# SF32LB56x register map
File version: 1.0
CPU: CM33 r0p1, little endian, MPU, FPU, 3 interrupt priority bits
Registers are 32-bit, read-write, reset 0x0 unless marked. A register's access mark holds for its fields unless they carry their own. Offsets are from the block's base; [hi:lo] are bit positions.

## MPI1
Base 0x40081000
Same registers: MPI2 0x40082000, MPI3 0x40083000, MPI4 0x40084000, MPI5 0x50081000
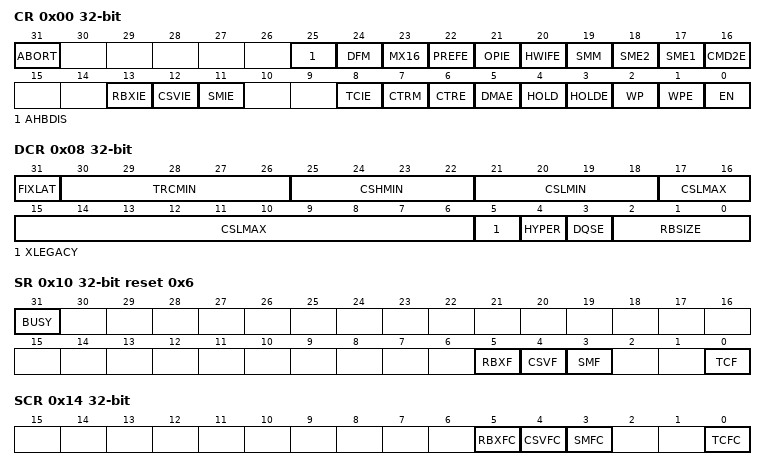
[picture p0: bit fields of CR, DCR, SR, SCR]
0x00 CR — Control Register
  [31] ABORT — Write 1 to abort internal state machine. For debug purpose only
  [25] AHBDIS — Hold hreadyout low if AHB access
  [24] DFM — Dual Flash ModeReserved-Do not modify
  [23] MX16 — Mode X16Reserved-Do not modify
  [22] PREFE — Prefetch enable. If enabled, MPI will prefetch at consequtive address following a read transaction. Recommend to use when reading large data in a burst manner. 0: prefetch disabled 1: prefetch enabled
  [21] OPIE — OPI interface enable 0: x8 mode disabled 1: x8 mode enabled
  [20] HWIFE — Hardware interface enableReserved-Do not modify
  [19] SMM — Status match mode 0: AND mode 1: OR mode
  [18] SME2 — Status match enable. If enabled, CMD2 will be issued repeatedly until the data match the value in SMR and SMKR 0: disabled 1: enabled
  [17] SME1 — Status match enable. If enabled, CMD1 will be issued repeatedly until the data match the value in SMR and SMKR 0: disabled 1: enabled (either SME1 or SME2 can be enabled, and SME1 has high priority)
  [16] CMD2E — Enable CMD2 0: disabled 1: CMD2 is enabled and will be issued after CMD1 with an interval of TI2
  [13] RBXIE — Row boundary crossing interrupt enable
  [12] CSVIE — CS max violation interrupt enable
  [11] SMIE — Status match interrupt enable
  [8] TCIE — Transfer complete interrupt enable
  [7] CTRM — AES-CTR mode 0: AES-128 1: AES-256
  [6] CTRE — AES-CTR on-the-fly decryption enable 0: disabled 1: enabled, data read from memory will be decrypted on the fly by MPI controller
  [5] DMAE — DMA enable 0: disabled 1: enable DMA to read or write DR register
  [4] HOLD — The value of HOLD when HOLDE is set
  [3] HOLDE — Enable HOLD function on IO3. Use this only in SPI or Dual SPI mode
  [2] WP — The value of WP when WPE is set
  [1] WPE — Enable WP function on IO2. Use this only in SPI or Dual SPI mode
  [0] EN — Enable MPI
0x04 DR — Data Register
  [31:0] DATA — The entry of internal data FIFO
0x08 DCR — Device Control Register
  [31] FIXLAT — Indicate PSRAM is fixed latency or variable latency. It must be compatible to the configuration in PSRAM registers. Recommend always set to 1. 0: variable latency 1: fixed latency
  [30:26] TRCMIN — Write/Read cycle minimum time in internal MCLK cycles. Please see MCLK frequency in PSCLR description. For example, if PSRAM clock is 120MHz (i.e. internal MCLK is 240MHz) and TRCMIN = n, then tRC time = (n+1) * 1000/240 ns which must meet minimum tRC requirement for PSRAM
  [25:22] CSHMIN — Minimum CS high deselect time in MCLK cycles. For example, if PSRAM clock is 120MHz (i.e. internal MCLK is 240MHz) and CSHMIN = n, then CS High time = (n+1) * 1000/240 ns which must meet minimum tCPH requirement for PSRAM
  [21:18] CSLMIN — Minimum CS low active time in MCLK cycles. For example, if PSRAM clock is 120MHz (i.e. internal MCLK is 240MHz) and CSLMIN = n, then CS Low time = (n+1) * 1000/240 ns which must meet the minimum tCEM requirement for PSRAM
  [17:6] CSLMAX — Maximum CS low active time in MCLK cycles For example, if PSRAM clock is 120MHz (i.e. internal MCLK is 240MHz) and CSLMAX = n, then CS Low time = (n+1) * 1000/240 ns which must meet the maximum tCEM requirement for PSRAM
  [5] XLEGACY — Xccela legacy protocol. Set to 1 for AP 32Mb PSRAM only, othersize always set to 0.
  [4] HYPER — HyperBus protocol. Set to 1 for HyperRAM.
  [3] DQSE — DQS enable. Setting to 1 indicates device provides DQS signal for Rx data latching
  [2:0] RBSIZE — Row boundary size. 0: no row boundary 1: 2^(1+3) = 16 bytes 2: 2^(2+3) = 32 bytes … n: 2^(n+3) bytes
0x0C PSCLR — Prescaler Register
  [7:0] DIV — Prescaler divider. 0: MCLK = FCLK/1 1: MCLK = FCLK/1 2: MCLK = FCLK/2 n: MCLK = FCLK/n Note: FLASH clock = MCLK. E.g. FCLK=192M and DIV=2, then FLASH clock = MCLK = 192/2 = 96MHz PSRAM clock = MCLK/2. E.g. FCLK=240M and DIV=1, then PSRAM clock = MCLK/2 = 240/2 = 120MHz
0x10 SR reset 0x6 — Status Register
  [31] BUSY — For debug purpose only
  [5] RBXF — Row boundary crossing flag
  [4] CSVF — CS max violation flag
  [3] SMF — Status match flag in Polling Mode
  [0] TCF — Transfer complete flag
0x14 SCR — Status Clear Register
  [5] RBXFC — Write 1 to clear RBXF
  [4] CSVFC — Write 1 to clear CSVF
  [3] SMFC — Write 1 to clear SMF
  [0] TCFC — Write 1 to clear TCF
0x18 CMDR1 — Command Register
  [7:0] CMD — Command. Write to this register will trigger the sequence specified in CCR1
0x1C AR1 — Address Register
  [31:0] ADDR — Address
0x20 ABR1 — Alternate Byte Register
  [31:0] ABYTE — Alternate byte
0x24 DLR1 — Data Length Register
  [19:0] DLEN — Data length 0: one byte 1: two bytes … n: (n+1) bytes
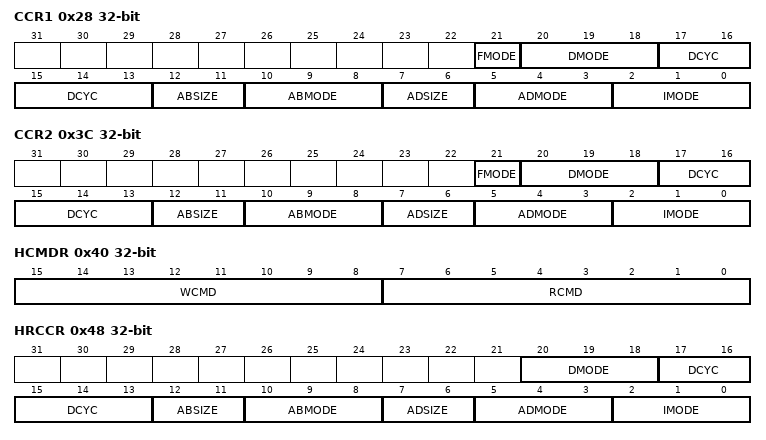
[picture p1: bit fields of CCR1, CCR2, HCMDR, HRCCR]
0x28 CCR1 — Communication Configuration Register
  [21] FMODE — Function Mode 0: read mode 1: write mode
  [20:18] DMODE — Data Mode 0: no data phase 1: single line 2: dual lines 3: quad lines 4/5/6: reserved 7: quad lines DDR
  [17:13] DCYC — Number of dummy cycles 0: no dummy cycle 1: one dummy cycle 2: two dummy cycles
  [12:11] ABSIZE — Alternate byte size 0: one byte 1: two bytes 2: three bytes 3: four bytes
  [10:8] ABMODE — Alternate byte mode 0: no alternate byte 1: single line 2: dual lines 3: quad lines 4/5/6: reserved 7: quad lines DDR
  [7:6] ADSIZE — Address size 0: one byte 1: two bytes 2: three bytes 3: four bytes
  [5:3] ADMODE — Address mode 0: no address phase 1: single line 2: dual line 3: quad line 4/5/6: reserved 7: quad line DDR
  [2:0] IMODE — Instruction mode 0: no instruction phase 1: single line 2: dual lines 3: quad lines 4/5/6 - reserved 7 - quad lines DDR
0x2C CMDR2 — Command Register
  [7:0] CMD — Command 2. If CMD2E is enabled, the CMD2 sequence will be issued after CMD1 as specified in CCR2 Note: CMD2 sequence cannot be issue individually
0x30 AR2 — Address Register
  [31:0] ADDR — Address byte in CMD2 sequence
0x34 ABR2 — Alternate Byte Register
  [31:0] ABYTE — Alternate byte in CMD2 sequence
0x38 DLR2 — Data Length Register
  [19:0] DLEN — Data length in CMD2 sequence
0x3C CCR2 — Communication Configuration Register
  [21] FMODE
  [20:18] DMODE
  [17:13] DCYC
  [12:11] ABSIZE
  [10:8] ABMODE
  [7:6] ADSIZE
  [5:3] ADMODE
  [2:0] IMODE — This register specifies the format of CMD2 sequence. Refer to CCR1 description
0x40 HCMDR — AHB Command Register
  [15:8] WCMD — AHB write command. During XIP, the AHB write transaction will be translated into this Write Command on memory interface
  [7:0] RCMD — AHB read command. During XIP, the AHB read transaction will be translated into this Read Command on memory interface
0x44 HRABR — AHB Read Alternate Byte Register
  [31:0] ABYTE
0x48 HRCCR — AHB Read Communication Configuration Register
  [20:18] DMODE
  [17:13] DCYC
  [12:11] ABSIZE
  [10:8] ABMODE
  [7:6] ADSIZE
  [5:3] ADMODE
  [2:0] IMODE — This register specifies the format of AHB read command sequence. Refer to CCR1 description
0x4C HWABR — AHB Write Alternate Byte Register
  [31:0] ABYTE
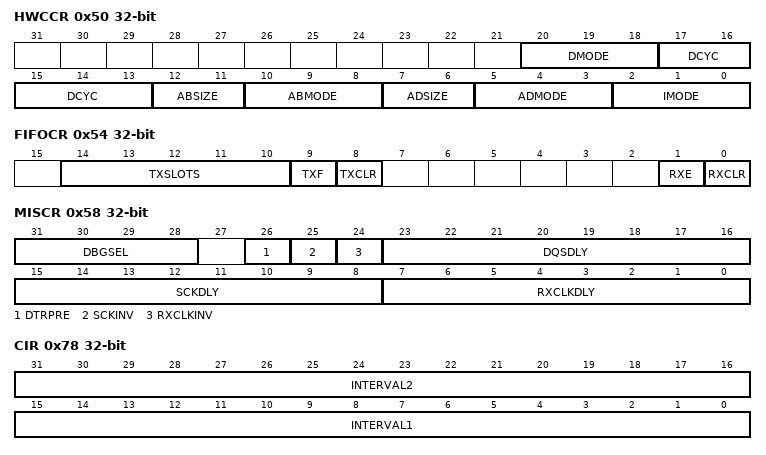
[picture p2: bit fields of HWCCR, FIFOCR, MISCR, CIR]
0x50 HWCCR — AHB Write Communication Configuration Register
  [20:18] DMODE
  [17:13] DCYC
  [12:11] ABSIZE
  [10:8] ABMODE
  [7:6] ADSIZE
  [5:3] ADMODE
  [2:0] IMODE — This register specifies the format of AHB write command sequence. Refer to CCR1 description
0x54 FIFOCR — FIFO Control Register
  [14:10] TXSLOTS — When DMA enabled, asserts DMA reqeust if TXFIFO vacant slots is greater than or equal to TXSLOTS. Note: this field should be set in accordance to the burst length in DMA. For example, if DMA employs BURST8 transction, then this filed is set to 8
  [9] TXF — Tx FIFO full flag
  [8] TXCLR — write 1 to clear Tx FIFO
  [1] RXE — Rx FIFO empty
  [0] RXCLR — write 1 to clear Rx FIFO
0x58 MISCR — Miscelaneous Register
  [31:28] DBGSEL
  [26] DTRPRE — Enable pre-sampling for DTRReserved-Do not modify
  [25] SCKINV — Invert output clock. This bit is used to align (coarse tune) the output clock to the center of output data.
  [24] RXCLKINV — Invert internal Rx clock to add half-cycle delay (coarse tune) when sampling data. It is usually used for FLASH device w/ higher frequency.
  [23:16] DQSDLY — Delay the input DQS signal to the appropriate sampling position. For device w/ DQS signal only. Note: effective 7-bit
  [15:8] SCKDLY — Add delay on output clock to fine tune the clock position. Note: effective 7-bit
  [7:0] RXCLKDLY — Add delay on internal Rx clock to fine tune the sampling position. Note: effective 5-bit
0x5C CTRSAR — CTR Starting Address Register
  [31:10] SA — Starting address of the AES decryption area. Since the lowest 10 bits are zero, the address is always 1KB aligned. Together with CTREAR, the total area is [CTRSAR, CTREAR) For example, CTRSAR = 32'h0, CTREAR = 32'h200000, then the on-the-fly decryption area is 0x0 - 0x1FFFFF
0x60 CTREAR — CTR Ending Address Register
  [31:10] EA — Ending address of the AES decryption area
0x64 NONCEA
  [31:0] NONCEA — Used for on-the-fly decryption
0x68 NONCEB
  [31:0] NONCEB — Used for on-the-fly decryption
0x6C AASAR — Address Aliasing Start Address Register
  [31:10] SA — Starting address of the address aliasing area. Always 1KB aligned.Together with AAEAR, the aliasing area is [AASAR, AAEAR). If the address falls into this area, an offset AAOAR is added and the aliased address will be used to access external memory
0x70 AAEAR — Address Aliasing Ending Address Register
  [31:10] EA — Ending address of the address aliasing area
0x74 AAOAR — Address Aliasing Offset Address Register
  [31:10] OA — The offset to be added to the original address
0x78 CIR — Command Interval Register
  [31:16] INTERVAL2 — The interval between CMD1 and CMD2 (or between CMD2 itself) if CMD2E is enabled. The unit is in MCLK cycles
  [15:0] INTERVAL1 — The interval between CMD1 itself. The unit is in MCLK cycles
0x7C SMR — Status Match Register
  [31:0] STATUS — If status match is enabled, this register is compared with the data read from external memory. Together with SMKR, only the bits with mask=1 will be considered to compare in AND or OR mode as configured in SMM field.
0x80 SMKR — Status Mask Register
  [31:0] MASK — Status mask 0: the corresponding bit is not considered to compare 1: the corresponding bit is considered to compare
0x84 TIMR — Timer Register
  [15:0] TIMEOUT — After the transaction is complete, CS remains low for multiple cycles of MCLK as specified by this register. For example if TIMEOUT=n, CS remains active for n cycles, during which if a new transaction occurs and the address is consecutive, the memory access can be resumed w/o sending the command and address again.
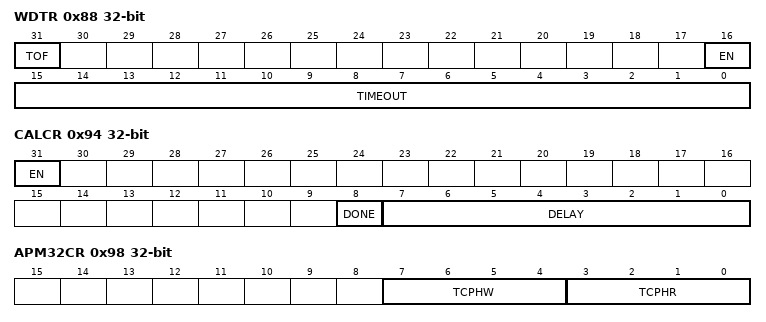
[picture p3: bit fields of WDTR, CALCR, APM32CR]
0x88 WDTR — WDT Register
  [31] TOF — Timeout flag. Self cleared when HREADYOUT becomes ready
  [16] EN — WDT enable. This watchdog is on AHB side such that bus access will not hang in exceptional cases
  [15:0] TIMEOUT — Set timeout value in number of clk_wdt cycles
0x8C PRSAR — Prefetch Starting Address Register
  [31:10] SA — Starting address of the prefetch area If prefetch is enabled and the read address falls into [PRSAR, PREAR), controller will prefetch the following data
0x90 PREAR — Prefetch Ending Address Register
  [31:10] EA — Ending address of the prefetch area
0x94 CALCR — Calibration Clock Register
  [31] EN — calibration enable
  [8] DONE — calibration done flag
  [7:0] DELAY — calibration delay result
0x98 APM32CR — APM32 Control Register
  [7:4] TCPHW — For special use by AP 32Mb PSRAM.Reserved-Do not modify
  [3:0] TCPHR — For special use by AP 32Mb PSRAM.Reserved-Do not modify
0x9C CR2 — Control Register 2
  [7:0] LOOP — Repeat CMD1->CMD2 sequence for n times. This filed is only valid when CMD2E=1 and SME2=0. For example if LOOP=0, then the sequence is CMD1 -> CMD2. If LOOP=2, then the sequence is (CMD1->CMD2) -> (CMD1->CMD2) -> (CMD1->CMD2)
